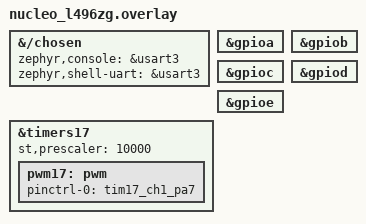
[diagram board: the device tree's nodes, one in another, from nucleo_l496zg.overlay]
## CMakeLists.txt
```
cmake_minimum_required(VERSION 3.20.0)

find_package(Zephyr REQUIRED HINTS $ENV{ZEPHYR_BASE})

project(mecanum)

target_sources(app PRIVATE
    src/main.c
    src/zephyr_motor.c
    src/zephyr_encoder.c
    src/zephyr_accelmotor.c
    src/zephyr_ps2.c
)

target_include_directories(app PRIVATE src)
```

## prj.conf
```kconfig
CONFIG_GPIO=y

CONFIG_PWM=y

CONFIG_COUNTER=y

CONFIG_CONSOLE=y

CONFIG_SERIAL=y

CONFIG_LOG=y

CONFIG_LOG_MODE_IMMEDIATE=y


CONFIG_UART_INTERRUPT_DRIVEN=y

CONFIG_MAIN_STACK_SIZE=4096

CONFIG_THREAD_MONITOR=y


CONFIG_CLOCK_CONTROL=y

CONFIG_PINCTRL=y

CONFIG_FPU=y

CONFIG_FPU_SHARING=y
```

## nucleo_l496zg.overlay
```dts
/*
 * Overlay for mecanum project on NUCLEO-L496ZG.
 *
 * Notes:
 * - Motor direction, PS2, and speed sensors are configured via GPIO API in code.
 * - PWM for TIM1/TIM2 is already enabled in board DTS (labels pwm1 and pwm2).
 * - We additionally enable TIM17 PWM on PA7 for BR motor.
 */

&{/chosen} {
    zephyr,console = &usart3;
    zephyr,shell-uart = &usart3;
};

&gpioa {
    status = "okay";
};

&gpiob {
    status = "okay";
};

&gpioc {
    status = "okay";
};

&gpiod {
    status = "okay";
};

&gpioe {
    status = "okay";
};

&timers17 {
    status = "okay";
    st,prescaler = <10000>;

    pwm17: pwm {
        status = "okay";
        pinctrl-0 = <&tim17_ch1_pa7>;
        pinctrl-names = "default";
    };
};
```

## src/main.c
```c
#include <zephyr/kernel.h>
#include <zephyr/device.h>
#include <zephyr/drivers/gpio.h>
#include <zephyr/drivers/pwm.h>
#include <zephyr/drivers/sensor.h>
#include <zephyr/logging/log.h>

#include "zephyr_motor.h"
#include "zephyr_encoder.h"
#include "zephyr_accelmotor.h"
#include "zephyr_ps2.h"

LOG_MODULE_REGISTER(main, LOG_LEVEL_INF);

// конфигурация
#define MAX_SPEED           70      // макс. скорость в тиках/сек
#define MIN_DUTY            30      // минимальный ШИМ для трогания с места
#define STEP_SIZE           50      // шаг перемещения по кнопкам
#define ACCEL               7       // ускорение
#define MAX_FOLLOW_SPEED    500     // макс. скорость слежения
#define DT_MS               20      // период дискретизации
#define MOTOR_AUTOTEST_NO_PS2 1     // 1: автотест моторов без геймпада PS2
#define AUTOTEST_SPEED      35      // сниженный duty для щадящего теста силовой части
#define AUTOTEST_STEP_MS    2000

// ПИД коэф-ты
#define PID_P   2.2f
#define PID_I   0.4f
#define PID_D   0.01f

// моторы
static zephyr_motor_t motor_fl, motor_fr, motor_bl, motor_br;

#if !MOTOR_AUTOTEST_NO_PS2
// энкодеры
static zephyr_encoder_t enc_fl, enc_fr, enc_bl, enc_br;

// доп. функции моторов
static zephyr_accelmotor_t accel_fl, accel_fr, accel_bl, accel_br;
#endif

// PS2 контроллер
#if !MOTOR_AUTOTEST_NO_PS2
static ps2_t ps2;

// режим
static bool position_mode = false;  // false - speed mode, true - position mode
static int32_t pos_fl = 0, pos_fr = 0, pos_bl = 0, pos_br = 0;

static void update_target_positions(void) {
    zephyr_accelmotor_set_target_pos(&accel_fl, pos_fl);
    zephyr_accelmotor_set_target_pos(&accel_fr, pos_fr);
    zephyr_accelmotor_set_target_pos(&accel_bl, pos_bl);
    zephyr_accelmotor_set_target_pos(&accel_br, pos_br);
}

// переключение режимов
static void change_mode(bool mode) {
    position_mode = mode;

    if (mode) {
        // переключение всех моторов в режим position
        zephyr_accelmotor_set_run_mode(&accel_fl, ACCEL_POS);
        zephyr_accelmotor_set_run_mode(&accel_fr, ACCEL_POS);
        zephyr_accelmotor_set_run_mode(&accel_bl, ACCEL_POS);
        zephyr_accelmotor_set_run_mode(&accel_br, ACCEL_POS);

        // Обновляем текущие позиции
        pos_fl = zephyr_accelmotor_get_current_pos(&accel_fl);
        pos_fr = zephyr_accelmotor_get_current_pos(&accel_fr);
        pos_bl = zephyr_accelmotor_get_current_pos(&accel_bl);
        pos_br = zephyr_accelmotor_get_current_pos(&accel_br);

        update_target_positions();

        LOG_INF("Switched to POSITION mode");
    } else {
        // переключение всех моторов в режим speed
        zephyr_accelmotor_set_run_mode(&accel_fl, PID_SPEED);
        zephyr_accelmotor_set_run_mode(&accel_fr, PID_SPEED);
        zephyr_accelmotor_set_run_mode(&accel_bl, PID_SPEED);
        zephyr_accelmotor_set_run_mode(&accel_br, PID_SPEED);

        LOG_INF("Switched to SPEED mode");
    }
}
#endif

static K_MUTEX_DEFINE(control_lock);

// управление моторами
void motor_control_thread(void *, void *, void *) {
    LOG_INF("Motor control thread started");

    while (1) {
#if MOTOR_AUTOTEST_NO_PS2
        k_sleep(K_MSEC(100));
        continue;
#else
        static uint32_t last_print = 0;
        k_mutex_lock(&control_lock, K_FOREVER);

        // чтение энкодеров
        int32_t enc_fl_val = zephyr_encoder_get_count(&enc_fl);
        int32_t enc_fr_val = zephyr_encoder_get_count(&enc_fr);
        int32_t enc_bl_val = zephyr_encoder_get_count(&enc_bl);
        int32_t enc_br_val = zephyr_encoder_get_count(&enc_br);

        // Обновление моторов
        bool moving1 = zephyr_accelmotor_tick(&accel_fl, enc_fl_val);
        bool moving2 = zephyr_accelmotor_tick(&accel_fr, enc_fr_val);
        bool moving3 = zephyr_accelmotor_tick(&accel_bl, enc_bl_val);
        bool moving4 = zephyr_accelmotor_tick(&accel_br, enc_br_val);

        if (position_mode && !moving1 && !moving2 && !moving3 && !moving4) {
            LOG_INF("All motors stopped, switching to speed mode");
            change_mode(false);
        }

        // вывод отладочной информации
        uint32_t now = k_uptime_get_32();
        if (now - last_print > 1000) {
            last_print = now;

            if (position_mode) {
                LOG_INF("Pos: FL=%d FR=%d BL=%d BR=%d | Target: FL=%d FR=%d",
                        zephyr_accelmotor_get_current_pos(&accel_fl),
                        zephyr_accelmotor_get_current_pos(&accel_fr),
                        zephyr_accelmotor_get_current_pos(&accel_bl),
                        zephyr_accelmotor_get_current_pos(&accel_br),
                        zephyr_accelmotor_get_target_pos(&accel_fl),
                        zephyr_accelmotor_get_target_pos(&accel_fr));
            } else {
                LOG_INF("Speed: FL=%d FR=%d BL=%d BR=%d | Duty: FL=%.1f FR=%.1f",
                        zephyr_accelmotor_get_current_speed(&accel_fl),
                        zephyr_accelmotor_get_current_speed(&accel_fr),
                        zephyr_accelmotor_get_current_speed(&accel_bl),
                        zephyr_accelmotor_get_current_speed(&accel_br),
                        zephyr_accelmotor_get_duty(&accel_fl),
                        zephyr_accelmotor_get_duty(&accel_fr));
            }
        }

        k_mutex_unlock(&control_lock);
        k_sleep(K_MSEC(DT_MS));
#endif
    }
}

// PS2
void ps2_thread(void *, void *, void *) {
    LOG_INF("PS2 thread started");

    while (1) {
#if MOTOR_AUTOTEST_NO_PS2
        static int last_phase = -1;
        uint32_t phase = (k_uptime_get_32() / AUTOTEST_STEP_MS) % 3U;

        k_mutex_lock(&control_lock, K_FOREVER);

        if (phase == 0U) {
            zephyr_motor_set_speed(&motor_fl, AUTOTEST_SPEED);
            zephyr_motor_set_speed(&motor_fr, AUTOTEST_SPEED);
            zephyr_motor_set_speed(&motor_bl, AUTOTEST_SPEED);
            zephyr_motor_set_speed(&motor_br, AUTOTEST_SPEED);
        } else if (phase == 1U) {
            zephyr_motor_set_speed(&motor_fl, -AUTOTEST_SPEED);
            zephyr_motor_set_speed(&motor_fr, -AUTOTEST_SPEED);
            zephyr_motor_set_speed(&motor_bl, -AUTOTEST_SPEED);
            zephyr_motor_set_speed(&motor_br, -AUTOTEST_SPEED);
        } else {
            zephyr_motor_set_speed(&motor_fl, 0);
            zephyr_motor_set_speed(&motor_fr, 0);
            zephyr_motor_set_speed(&motor_bl, 0);
            zephyr_motor_set_speed(&motor_br, 0);
        }
        k_mutex_unlock(&control_lock);

        if ((int)phase != last_phase) {
            last_phase = (int)phase;
            if (phase == 0U) {
                LOG_INF("AUTOTEST: FORWARD");
            } else if (phase == 1U) {
                LOG_INF("AUTOTEST: BACKWARD");
            } else {
                LOG_INF("AUTOTEST: STOP");
            }
        }

        k_sleep(K_MSEC(50));
        continue;
#else
        bool success = ps2_read_gamepad(&ps2, false, 0);

        if (success) {
            k_mutex_lock(&control_lock, K_FOREVER);

            // кнопки крестовины
            if (ps2_button_pressed(&ps2, PSB_PAD_LEFT)) {
                LOG_INF("Move LEFT");
                change_mode(true);

                pos_fl += STEP_SIZE;
                pos_fr -= STEP_SIZE;
                pos_bl -= STEP_SIZE;
                pos_br += STEP_SIZE;

                update_target_positions();
            }

            if (ps2_button_pressed(&ps2, PSB_PAD_RIGHT)) {
                LOG_INF("Move RIGHT");
                change_mode(true);

                pos_fl -= STEP_SIZE;
                pos_fr += STEP_SIZE;
                pos_bl += STEP_SIZE;
                pos_br -= STEP_SIZE;

                update_target_positions();
            }

            if (ps2_button_pressed(&ps2, PSB_PAD_UP)) {
                LOG_INF("Move UP");
                change_mode(true);

                pos_fl += STEP_SIZE;
                pos_fr += STEP_SIZE;
                pos_bl += STEP_SIZE;
                pos_br += STEP_SIZE;

                update_target_positions();
            }

            if (ps2_button_pressed(&ps2, PSB_PAD_DOWN)) {
                LOG_INF("Move DOWN");
                change_mode(true);

                pos_fl -= STEP_SIZE;
                pos_fr -= STEP_SIZE;
                pos_bl -= STEP_SIZE;
                pos_br -= STEP_SIZE;

                update_target_positions();
            }

            // скоростной режим (стики)
            if (!position_mode) {
                // чтение стиков и преобразование их в скорости
                int val_lx = (int)ps2_analog(&ps2, PSS_LX) - 128;
                int val_ly = (int)ps2_analog(&ps2, PSS_LY) - 128;
                int val_rx = (int)ps2_analog(&ps2, PSS_RX) - 128;
                int val_ry = (int)ps2_analog(&ps2, PSS_RY) - 128;

                val_lx = val_lx * MAX_SPEED / 128;
                val_ly = val_ly * MAX_SPEED / 128;
                val_rx = val_rx * MAX_SPEED / 128;
                val_ry = val_ry * MAX_SPEED / 128;

                int duty_fr = val_ly + val_lx;
                int duty_fl = val_ly - val_lx;
                int duty_br = val_ly - val_lx;
                int duty_bl = val_ly + val_lx;

                // вращение
                duty_fr += val_ry - val_rx;
                duty_fl += val_ry + val_rx;
                duty_br += val_ry - val_rx;
                duty_bl += val_ry + val_rx;

                // ограничение
                if (duty_fr > MAX_SPEED) duty_fr = MAX_SPEED;
                if (duty_fr < -MAX_SPEED) duty_fr = -MAX_SPEED;
                if (duty_fl > MAX_SPEED) duty_fl = MAX_SPEED;
                if (duty_fl < -MAX_SPEED) duty_fl = -MAX_SPEED;
                if (duty_br > MAX_SPEED) duty_br = MAX_SPEED;
                if (duty_br < -MAX_SPEED) duty_br = -MAX_SPEED;
                if (duty_bl > MAX_SPEED) duty_bl = MAX_SPEED;
                if (duty_bl < -MAX_SPEED) duty_bl = -MAX_SPEED;

                zephyr_accelmotor_set_target_speed(&accel_fl, duty_fl);
                zephyr_accelmotor_set_target_speed(&accel_fr, duty_fr);
                zephyr_accelmotor_set_target_speed(&accel_bl, duty_bl);
                zephyr_accelmotor_set_target_speed(&accel_br, duty_br);
            }

            k_mutex_unlock(&control_lock);
        } else {
            k_mutex_lock(&control_lock, K_FOREVER);
            // остановка моторов при потери связи с PS2
            LOG_WRN("PS2 lost, stopping motors");
            change_mode(false);
            zephyr_accelmotor_set_target_speed(&accel_fl, 0);
            zephyr_accelmotor_set_target_speed(&accel_fr, 0);
            zephyr_accelmotor_set_target_speed(&accel_bl, 0);
            zephyr_accelmotor_set_target_speed(&accel_br, 0);
            k_mutex_unlock(&control_lock);
        }

        k_sleep(K_MSEC(50));
#endif
    }
}

static bool init_hardware(void) {
    LOG_INF("Initializing hardware...");

    const struct device *pwm_dev1 = DEVICE_DT_GET(DT_NODELABEL(pwm1));
    const struct device *pwm_dev2 = DEVICE_DT_GET(DT_NODELABEL(pwm2));
    const struct device *pwm_dev17 = DEVICE_DT_GET(DT_NODELABEL(pwm17));

    const struct device *gpio_dev_b = DEVICE_DT_GET(DT_NODELABEL(gpiob));
    const struct device *gpio_dev_e = DEVICE_DT_GET(DT_NODELABEL(gpioe));
    const struct device *gpio_dev_a = DEVICE_DT_GET(DT_NODELABEL(gpioa));
    const struct device *gpio_dev_c = DEVICE_DT_GET(DT_NODELABEL(gpioc));
    const struct device *gpio_dev_d = DEVICE_DT_GET(DT_NODELABEL(gpiod));

    // проверка устройств
    if (!device_is_ready(pwm_dev1)) {
        LOG_ERR("TIM1 not ready");
        return false;
    }
    if (!device_is_ready(pwm_dev2)) {
        LOG_ERR("TIM2 not ready");
        return false;
    }
    if (!device_is_ready(pwm_dev17)) {
        LOG_ERR("TIM17 not ready");
        return false;
    }
    if (!device_is_ready(gpio_dev_b)) {
        LOG_ERR("GPIOB not ready");
        return false;
    }
    if (!device_is_ready(gpio_dev_e)) {
        LOG_ERR("GPIOE not ready");
        return false;
    }
    if (!device_is_ready(gpio_dev_a)) {
        LOG_ERR("GPIOA not ready");
        return false;
    }
    if (!device_is_ready(gpio_dev_c)) {
        LOG_ERR("GPIOC not ready");
        return false;
    }
    if (!device_is_ready(gpio_dev_d)) {
        LOG_ERR("GPIOD not ready");
        return false;
    }

    // FL мотор: DIR PB13 (A-1B), PWM TIM1_CH1/PE9 (A-1A)
    zephyr_motor_init(&motor_fl, pwm_dev1, 1, gpio_dev_b, 13, false);
    zephyr_motor_set_min_duty(&motor_fl, MIN_DUTY);
    zephyr_motor_set_max_duty(&motor_fl, MAX_SPEED);

    // FR мотор: DIR PE10 (A-1B), PWM TIM1_CH2/PE11 (A-1A)
    zephyr_motor_init(&motor_fr, pwm_dev1, 2, gpio_dev_e, 10, false);
    zephyr_motor_set_min_duty(&motor_fr, MIN_DUTY);
    zephyr_motor_set_max_duty(&motor_fr, MAX_SPEED);

    // BL мотор: DIR PB8 (B-1B), PWM TIM2_CH1/PA0 (B-1A)
    zephyr_motor_init(&motor_bl, pwm_dev2, 1, gpio_dev_b, 8, false);
    zephyr_motor_set_min_duty(&motor_bl, MIN_DUTY);
    zephyr_motor_set_max_duty(&motor_bl, MAX_SPEED);

    // BR мотор: DIR PA5 (B-1B), PWM TIM17_CH1/PA7 (B-1A)
    zephyr_motor_init(&motor_br, pwm_dev17, 1, gpio_dev_a, 5, false);
    zephyr_motor_set_min_duty(&motor_br, MIN_DUTY);
    zephyr_motor_set_max_duty(&motor_br, MAX_SPEED);
    

#if !MOTOR_AUTOTEST_NO_PS2
    if (!zephyr_encoder_init(&enc_fl, gpio_dev_b, 6)) return false;
    if (!zephyr_encoder_init(&enc_fr, gpio_dev_c, 6)) return false;
    if (!zephyr_encoder_init(&enc_bl, gpio_dev_e, 8)) return false;
    if (!zephyr_encoder_init(&enc_br, gpio_dev_d, 3)) return false;

    // инициализация доп. функций моторов
    zephyr_accelmotor_init(&accel_fl, &motor_fl, &enc_fl);
    zephyr_accelmotor_init(&accel_fr, &motor_fr, &enc_fr);
    zephyr_accelmotor_init(&accel_bl, &motor_bl, &enc_bl);
    zephyr_accelmotor_init(&accel_br, &motor_br, &enc_br);

    // настройка параметров
    zephyr_accelmotor_set_dt(&accel_fl, DT_MS);
    zephyr_accelmotor_set_dt(&accel_fr, DT_MS);
    zephyr_accelmotor_set_dt(&accel_bl, DT_MS);
    zephyr_accelmotor_set_dt(&accel_br, DT_MS);

    zephyr_accelmotor_set_run_mode(&accel_fl, PID_SPEED);
    zephyr_accelmotor_set_run_mode(&accel_fr, PID_SPEED);
    zephyr_accelmotor_set_run_mode(&accel_bl, PID_SPEED);
    zephyr_accelmotor_set_run_mode(&accel_br, PID_SPEED);

    zephyr_accelmotor_set_acceleration(&accel_fl, ACCEL);
    zephyr_accelmotor_set_acceleration(&accel_fr, ACCEL);
    zephyr_accelmotor_set_acceleration(&accel_bl, ACCEL);
    zephyr_accelmotor_set_acceleration(&accel_br, ACCEL);

    zephyr_accelmotor_set_max_speed(&accel_fl, MAX_FOLLOW_SPEED);
    zephyr_accelmotor_set_max_speed(&accel_fr, MAX_FOLLOW_SPEED);
    zephyr_accelmotor_set_max_speed(&accel_bl, MAX_FOLLOW_SPEED);
    zephyr_accelmotor_set_max_speed(&accel_br, MAX_FOLLOW_SPEED);

    zephyr_accelmotor_set_stopzone(&accel_fl, 5);
    zephyr_accelmotor_set_stopzone(&accel_fr, 5);
    zephyr_accelmotor_set_stopzone(&accel_bl, 5);
    zephyr_accelmotor_set_stopzone(&accel_br, 5);

    // ПИД коэф-ты
    accel_fl.kp = PID_P;
    accel_fr.kp = PID_P;
    accel_bl.kp = PID_P;
    accel_br.kp = PID_P;

    accel_fl.ki = PID_I;
    accel_fr.ki = PID_I;
    accel_bl.ki = PID_I;
    accel_br.ki = PID_I;

    accel_fl.kd = PID_D;
    accel_fr.kd = PID_D;
    accel_bl.kd = PID_D;
    accel_br.kd = PID_D;
#endif

    // инициализация PS2
#if MOTOR_AUTOTEST_NO_PS2
    LOG_WRN("PS2 init skipped: MOTOR_AUTOTEST_NO_PS2=1");
#else
    if (!ps2_init(&ps2, gpio_dev_c, 8, 12, 10, 11, false, false)) {
        LOG_ERR("Failed to initialize PS2 controller");
        return false;
    } else {
        LOG_INF("PS2 controller initialized successfully");
    }
#endif

    LOG_INF("Hardware initialization complete");
    return true;
}

K_THREAD_STACK_DEFINE(motor_stack, 2048);
K_THREAD_STACK_DEFINE(ps2_stack, 2048);
static struct k_thread motor_thread_data;
static struct k_thread ps2_thread_data;

void main(void) {
    LOG_INF("Starting Mecanum robot on NUCLEO-L496ZG");
    if (!init_hardware()) {
        LOG_ERR("Hardware init failed");
        return;
    }

    k_thread_create(&motor_thread_data, motor_stack, K_THREAD_STACK_SIZEOF(motor_stack),
                    motor_control_thread, NULL, NULL, NULL, 5, 0, K_NO_WAIT);
    k_thread_name_set(&motor_thread_data, "motor_ctrl");

    k_thread_create(&ps2_thread_data, ps2_stack, K_THREAD_STACK_SIZEOF(ps2_stack),
                    ps2_thread, NULL, NULL, NULL, 4, 0, K_NO_WAIT);
    k_thread_name_set(&ps2_thread_data, "ps2_ctrl");

    LOG_INF("System ready");
}
```

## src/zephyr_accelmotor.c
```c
#include "zephyr_accelmotor.h"
#include <zephyr/logging/log.h>

LOG_MODULE_REGISTER(accelmotor, LOG_LEVEL_INF);

static int32_t iabs32(int32_t x) {
    return (x < 0) ? -x : x;
}

static float fabs32(float x) {
    return (x < 0.0f) ? -x : x;
}

static int8_t sign(float x) {
    return (x > 0) ? 1 : ((x < 0) ? -1 : 0);
}

void zephyr_accelmotor_init(zephyr_accelmotor_t *accel,
                            zephyr_motor_t *motor,
                            zephyr_encoder_t *encoder) {
    accel->motor = motor;
    accel->encoder = encoder;

    accel->ratio = 1.0f;
    accel->dt_ms = 20;
    accel->dt_sec = 0.02f;
    accel->stopzone = 8;
    accel->max_speed = 0;
    accel->acceleration = 1.0f;

    accel->run_mode = IDLE_RUN;
    accel->current_pos = 0;
    accel->last_pos = 0;
    accel->target_pos = 0;
    accel->current_speed = 0;
    accel->target_speed = 0;
    accel->duty_f = 0.0f;
    accel->last_tick_time = k_uptime_get();

    for (int i = 0; i < 3; i++) {
        accel->speed_buf[i] = 0;
    }
    accel->speed_buf_idx = 0;
    accel->filtered_speed = 0.0f;

    accel->kp = 2.0f;
    accel->ki = 0.9f;
    accel->kd = 0.1f;
    accel->integral = 0.0f;
    accel->prev_input = 0;
    accel->last_speed = 0.0f;

    accel->control_pos = 0.0f;
    accel->control_speed = 0.0f;
}

void zephyr_accelmotor_set_dt(zephyr_accelmotor_t *accel, uint32_t dt_ms) {
    accel->dt_ms = dt_ms;
    accel->dt_sec = dt_ms / 1000.0f;
}

void zephyr_accelmotor_set_ratio(zephyr_accelmotor_t *accel, float ratio) {
    accel->ratio = ratio;
}

void zephyr_accelmotor_set_stopzone(zephyr_accelmotor_t *accel, uint32_t zone) {
    accel->stopzone = zone;
}

void zephyr_accelmotor_set_run_mode(zephyr_accelmotor_t *accel, accel_run_mode_t mode) {
    accel->run_mode = mode;
    accel->integral = 0.0f;

    if (mode == ACCEL_POS) {
        accel->control_pos = (float)accel->current_pos;
        accel->control_speed = 0.0f;
    }
}

accel_run_mode_t zephyr_accelmotor_get_run_mode(zephyr_accelmotor_t *accel) {
    return accel->run_mode;
}

static int16_t filter_speed(zephyr_accelmotor_t *accel, int16_t new_speed) {
    accel->speed_buf[accel->speed_buf_idx] = new_speed;
    accel->speed_buf_idx = (accel->speed_buf_idx + 1) % 3;

    int16_t a = accel->speed_buf[0];
    int16_t b = accel->speed_buf[1];
    int16_t c = accel->speed_buf[2];

    int16_t median;
    if ((a <= b) && (a <= c)) {
        median = (b <= c) ? b : c;
    } else if ((b <= a) && (b <= c)) {
        median = (a <= c) ? a : c;
    } else {
        median = (a <= b) ? a : b;
    }

    accel->filtered_speed += (median - accel->filtered_speed) * 0.7f;
    return (int16_t)accel->filtered_speed;
}

static void pid_control(zephyr_accelmotor_t *accel, int32_t target, int32_t current, bool cutoff) {
    int32_t err = target - current;

    accel->duty_f = (float)err * accel->kp;
    accel->duty_f += (float)(accel->prev_input - current) * accel->kd / accel->dt_sec;
    accel->prev_input = current;

    accel->integral += (float)err * accel->ki * accel->dt_sec;
    accel->duty_f += accel->integral;

    uint16_t min_duty = 0;

    if (cutoff) {
        if (iabs32(err) > (int32_t)accel->stopzone) {
            accel->duty_f += sign(err) * min_duty;
        } else {
            accel->integral = 0.0f;
        }
    } else {
        if (err == 0 && target == 0) {
            accel->integral = 0.0f;
        } else {
            accel->duty_f += sign(err) * min_duty;
        }
    }

    if (accel->max_speed > 0) {
        if (accel->duty_f > accel->max_speed) accel->duty_f = (float)accel->max_speed;
        if (accel->duty_f < -accel->max_speed) accel->duty_f = -(float)accel->max_speed;
    }

    zephyr_motor_set_speed(accel->motor, (int16_t)accel->duty_f);
}

bool zephyr_accelmotor_tick(zephyr_accelmotor_t *accel, int32_t pos) {
    accel->current_pos = pos;
    uint32_t now = k_uptime_get();

    if (now - accel->last_tick_time >= accel->dt_ms) {
        accel->last_tick_time += accel->dt_ms;

        int32_t delta_pos = accel->current_pos - accel->last_pos;
        accel->current_speed = (int16_t)(delta_pos * 1000 / (int32_t)accel->dt_ms);
        accel->current_speed = filter_speed(accel, accel->current_speed);
        accel->last_pos = accel->current_pos;

        int8_t motor_dir = zephyr_motor_get_state(accel->motor);
        if (motor_dir != 0) {
            zephyr_encoder_set_direction(accel->encoder, motor_dir);
        }
        
        switch (accel->run_mode) {
            case ACCEL_POS: {
                float err = (float)(accel->target_pos - accel->control_pos);

                if (fabs32(err) > 0.1f) {
                    float accel_step = accel->acceleration * accel->dt_sec;

                    if (fabs32(err) < accel->stopzone &&
                        fabs32(accel->last_speed - accel->control_speed) < 2.0f) {
                        accel->control_pos = (float)accel->target_pos;
                        accel->control_speed = 0.0f;
                        accel_step = 0.0f;
                    }

                    if (fabs32(err) < (accel->control_speed * accel->control_speed) / (2.0f * accel->acceleration)) {
                        err = -err;
                        accel_step = (accel->control_speed * accel->control_speed) / (2.0f * fabs32(err));
                        if (sign(accel->control_speed) == sign(err)) err = -err;
                    }

                    accel->control_speed += accel_step * sign(err);

                    if (accel->max_speed > 0) {
                        float max_speed_dt = (float)accel->max_speed * accel->dt_sec;
                        if (accel->control_speed > max_speed_dt) accel->control_speed = max_speed_dt;
                        if (accel->control_speed < -max_speed_dt) accel->control_speed = -max_speed_dt;
                    }

                    accel->control_pos += accel->control_speed;
                    accel->last_speed = accel->control_speed;
                }

                pid_control(accel, (int32_t)accel->control_pos, accel->current_pos, true);
                break;
            }

            case PID_POS:
                pid_control(accel, accel->target_pos, accel->current_pos, true);
                break;

            case ACCEL_SPEED: {
                int16_t err = accel->target_speed - accel->current_speed;
                float reducer = (fabs32((float)err) < accel->acceleration) ? 1.0f : fabs32((float)err) / accel->acceleration;
                accel->duty_f += (float)sign(err) * accel->acceleration * accel->dt_sec * reducer;
                if (accel->max_speed > 0) {
                    if (accel->duty_f > accel->max_speed) accel->duty_f = (float)accel->max_speed;
                    if (accel->duty_f < -accel->max_speed) accel->duty_f = -(float)accel->max_speed;
                }
                zephyr_motor_set_speed(accel->motor, (int16_t)accel->duty_f);
                break;
            }

            case PID_SPEED:
                pid_control(accel, accel->target_speed, accel->current_speed, false);
                break;

            default:
                break;
        }
    }

    if (accel->run_mode > 1) {
        return zephyr_motor_get_state(accel->motor) != 0;
    } else {
        return (zephyr_motor_get_state(accel->motor) != 0) ||
               (iabs32(accel->target_pos - accel->current_pos) > (int32_t)accel->stopzone);
    }
}

void zephyr_accelmotor_set_target_pos(zephyr_accelmotor_t *accel, int32_t pos) {
    accel->target_pos = pos;
}

void zephyr_accelmotor_set_target_pos_deg(zephyr_accelmotor_t *accel, int32_t deg) {
    accel->target_pos = (int32_t)((float)deg * accel->ratio / 360.0f);
}

int32_t zephyr_accelmotor_get_target_pos(zephyr_accelmotor_t *accel) {
    return accel->target_pos;
}

int32_t zephyr_accelmotor_get_target_pos_deg(zephyr_accelmotor_t *accel) {
    return (int32_t)((float)accel->target_pos * 360.0f / accel->ratio);
}

void zephyr_accelmotor_set_target_speed(zephyr_accelmotor_t *accel, int16_t speed) {
    accel->target_speed = speed;
}

void zephyr_accelmotor_set_target_speed_deg(zephyr_accelmotor_t *accel, int16_t speed) {
    accel->target_speed = (int16_t)((float)speed * accel->ratio / 360.0f);
}

int16_t zephyr_accelmotor_get_target_speed(zephyr_accelmotor_t *accel) {
    return accel->target_speed;
}

int16_t zephyr_accelmotor_get_target_speed_deg(zephyr_accelmotor_t *accel) {
    return (int16_t)((float)accel->target_speed * 360.0f / accel->ratio);
}

int32_t zephyr_accelmotor_get_current_pos(zephyr_accelmotor_t *accel) {
    return accel->current_pos;
}

int32_t zephyr_accelmotor_get_current_pos_deg(zephyr_accelmotor_t *accel) {
    return (int32_t)((float)accel->current_pos * 360.0f / accel->ratio);
}

int16_t zephyr_accelmotor_get_current_speed(zephyr_accelmotor_t *accel) {
    return accel->current_speed;
}

int16_t zephyr_accelmotor_get_current_speed_deg(zephyr_accelmotor_t *accel) {
    return (int16_t)((float)accel->current_speed * 360.0f / accel->ratio);
}

float zephyr_accelmotor_get_duty(zephyr_accelmotor_t *accel) {
    return accel->duty_f;
}

void zephyr_accelmotor_set_max_speed(zephyr_accelmotor_t *accel, uint16_t speed) {
    accel->max_speed = speed;
}

void zephyr_accelmotor_set_max_speed_deg(zephyr_accelmotor_t *accel, uint16_t speed) {
    accel->max_speed = (uint16_t)((float)speed * accel->ratio / 360.0f);
}

void zephyr_accelmotor_set_acceleration(zephyr_accelmotor_t *accel, float accel_val) {
    accel->acceleration = accel_val;
}

void zephyr_accelmotor_set_acceleration_deg(zephyr_accelmotor_t *accel, float accel_val) {
    accel->acceleration = accel_val * accel->ratio / 360.0f;
}

bool zephyr_accelmotor_is_blocked(zephyr_accelmotor_t *accel) {
    uint16_t min_duty = 0;
    return (fabs32(accel->duty_f) > min_duty && accel->current_speed == 0);
}
```

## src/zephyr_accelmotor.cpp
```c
#include "zephyr_accelmotor.h"
#include <zephyr/logging/log.h>
#include <math.h>
#include <string.h>

LOG_MODULE_REGISTER(accel_motor, LOG_LEVEL_INF);

#define SIGN(x) ((x) > 0 ? 1 : ((x) < 0 ? -1 : 0))
#define MIN(a,b) ((a) < (b) ? (a) : (b))
#define MAX(a,b) ((a) > (b) ? (a) : (b))
#define ABS(x) ((x) > 0 ? (x) : -(x))

bool AccelMotor::tick(long pos) {
	_currentPos = pos;
	if (millis() - _tmr2 > _dt) {
		_tmr2 += _dt;
		_curSpeed = (long)(_currentPos - _lastPos) / _dts;
		_curSpeed = filter(_curSpeed);
		_lastPos = _currentPos;
		
		switch (_runMode) {		
		case ACCEL_POS:
			{
				long err = _targetPos - controlPos;
				if (err != 0) {
					float accelDt = _accel * _dts;
					float accel = accelDt;
					if (abs(err) < _stopzone && abs(_lastSpeed - controlSpeed) < 2) {
						controlPos = _targetPos;
						controlSpeed = 0;
						accel = 0;
					}
					if (abs(err) < (float)(controlSpeed * controlSpeed) / (2.0 * accelDt)) {
						err = -err;
						accel = (float)(controlSpeed * controlSpeed) / (2.0 * abs(err));
						if (_sign(controlSpeed) == _sign(err)) err = -err;
					}
					controlSpeed += accel * _sign(err);
					controlSpeed = constrain(controlSpeed, -_maxSpeed*_dts, _maxSpeed*_dts);
					controlPos += controlSpeed;
					_lastSpeed = controlSpeed;	
					
				}
				PIDcontrol(controlPos, _currentPos, true);
			}
			break;
		case PID_POS:				
			PIDcontrol(_targetPos, _currentPos, true);
			break;
		case ACCEL_SPEED:
			{
				int err = _targetSpeed - _curSpeed;
				float reducer = min(abs(err) / _accel, 1.0);
				_dutyF += (float)_sign(err) * _accel * _dts * reducer;
				_dutyF = constrain(_dutyF, -_maxDuty, _maxDuty);
				setSpeed(_dutyF);
			}			
			break;
		case PID_SPEED:			
			PIDcontrol(_targetSpeed, _curSpeed, false);			
			break;
		}		
	}
	if (_runMode > 1) return (getState() != 0);
	else return (getState() != 0 || abs(_targetPos - _currentPos) > _stopzone);
}

void AccelMotor::PIDcontrol(long target, long current, bool cutoff) {
	
	long err = target - current;
	_dutyF = err * kp;	
	_dutyF += (float)(_prevInput - current) * kd / _dts;
	_prevInput = current;
	integral += (float)err * ki * _dts;
	_dutyF += integral;	
	if (cutoff) {
		if (abs(err) > _stopzone) _dutyF += _sign(err)*_minDuty;
		else integral = 0;		
	} else {
		if (err == 0 && target == 0) integral = 0;
		else _dutyF += _sign(err)*_minDuty;
	}
	_dutyF = constrain(_dutyF, -_maxDuty, _maxDuty);
	setSpeed(_dutyF);
}

bool AccelMotor::isBlocked() {
	return (abs(_dutyF) > _minDuty && _curSpeed == 0);
}

// settings
void AccelMotor::setRatio(float ratio) {
	_ratio = ratio;
}
void AccelMotor::setDt(int dt) {
	_dt = dt;
	_dts = dt / 1000.0;
}
void AccelMotor::setCurrent(long pos) {	
	_currentPos = pos;
}
void AccelMotor::setRunMode(runMode mode) {
	_runMode = mode;
	if (mode == ACCEL_POS) controlPos = _currentPos;
}

// current position
long AccelMotor::getCurrent() {
	return _currentPos;
}
long AccelMotor::getCurrentDeg() {
	return (long)_currentPos * 360 / _ratio;
}

// current speed
int AccelMotor::getSpeed() {
	return _curSpeed;
}
int AccelMotor::getSpeedDeg() {
	return (long)_curSpeed * 360 / _ratio;
}
float AccelMotor::getDuty() {
	return _dutyF;
}

// target position mode
void AccelMotor::setTarget(long pos) {
	_targetPos = pos;
}
void AccelMotor::setTargetDeg(long pos) {
	_targetPos = (long)pos * _ratio / 360;	
}
long AccelMotor::getTarget() {
	return _targetPos;
}
long AccelMotor::getTargetDeg() {
	return (long)_targetPos * 360 / _ratio;
}

void AccelMotor::setStopZone(int zone) {
	_stopzone = zone;
}

// target speed mode
void AccelMotor::setTargetSpeed(int speed) {
	_targetSpeed = speed;
}
void AccelMotor::setTargetSpeedDeg(int speed) {
	_targetSpeed = (long)speed * _ratio / 360;	
}
int AccelMotor::getTargetSpeed() {
	return _targetSpeed;
}
int AccelMotor::getTargetSpeedDeg() {
	return (long)_targetSpeed * 360 / _ratio;
}

// max speed / acceleration
void AccelMotor::setMaxSpeed(int speed) {
	_maxSpeed = speed;
}
void AccelMotor::setMaxSpeedDeg(int speed) {
	_maxSpeed = (long)speed * _ratio / 360;
}
void AccelMotor::setAcceleration(float accel) {
	_accel = accel;
}
void AccelMotor::setAccelerationDeg(float accel) {
	_accel = (float)accel * _ratio / 360.0;
}


int AccelMotor::filter(int newVal) {
	_buf[_count] = newVal;
	if (++_count >= 3) _count = 0;
	int middle = 0;
	if ((_buf[0] <= _buf[1]) && (_buf[0] <= _buf[2])) {
		middle = (_buf[1] <= _buf[2]) ? _buf[1] : _buf[2];
	} else {
		if ((_buf[1] <= _buf[0]) && (_buf[1] <= _buf[2])) {
			middle = (_buf[0] <= _buf[2]) ? _buf[0] : _buf[2];
		}
		else {
			middle = (_buf[0] <= _buf[1]) ? _buf[0] : _buf[1];
		}
	}
	_middle_f += (middle-_middle_f) * 0.7;
	return _middle_f;
}
```

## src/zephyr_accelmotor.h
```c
#ifndef ZEPHYR_ACCELMOTOR_H
#define ZEPHYR_ACCELMOTOR_H

#include "zephyr_motor.h"
#include "zephyr_encoder.h"

#ifdef __cplusplus
extern "C" {
#endif

typedef enum {
    ACCEL_POS,      // позиционирование с ускорением
    PID_POS,        // ПИД позиционирование
    ACCEL_SPEED,    // скорость с ускорением
    PID_SPEED,      // ПИД скорость
    IDLE_RUN
} accel_run_mode_t;

typedef struct {
    zephyr_motor_t *motor;
    zephyr_encoder_t *encoder;

    float ratio;            // передаточное число
    uint32_t dt_ms;         // период (мс)
    float dt_sec;           // период (сек)
    uint32_t stopzone;      // зона остановки
    uint16_t max_speed;     // макс. скорость
    float acceleration;     // ускорение

    accel_run_mode_t run_mode;
    int32_t current_pos;
    int32_t last_pos;
    int32_t target_pos;
    int16_t current_speed;
    int16_t target_speed;
    float duty_f;
    uint32_t last_tick_time;

    int16_t speed_buf[3];
    uint8_t speed_buf_idx;
    float filtered_speed;

    float kp, ki, kd;
    float integral;
    int32_t prev_input;
    float last_speed;

    float control_pos;
    float control_speed;
} zephyr_accelmotor_t;

// инициализация
void zephyr_accelmotor_init(zephyr_accelmotor_t *accel,
                            zephyr_motor_t *motor,
                            zephyr_encoder_t *encoder);

bool zephyr_accelmotor_tick(zephyr_accelmotor_t *accel, int32_t pos);

// настройки
void zephyr_accelmotor_set_dt(zephyr_accelmotor_t *accel, uint32_t dt_ms);
void zephyr_accelmotor_set_ratio(zephyr_accelmotor_t *accel, float ratio);
void zephyr_accelmotor_set_stopzone(zephyr_accelmotor_t *accel, uint32_t zone);
void zephyr_accelmotor_set_run_mode(zephyr_accelmotor_t *accel, accel_run_mode_t mode);
accel_run_mode_t zephyr_accelmotor_get_run_mode(zephyr_accelmotor_t *accel);

void zephyr_accelmotor_set_target_pos(zephyr_accelmotor_t *accel, int32_t pos);
void zephyr_accelmotor_set_target_pos_deg(zephyr_accelmotor_t *accel, int32_t deg);
int32_t zephyr_accelmotor_get_target_pos(zephyr_accelmotor_t *accel);
int32_t zephyr_accelmotor_get_target_pos_deg(zephyr_accelmotor_t *accel);

void zephyr_accelmotor_set_target_speed(zephyr_accelmotor_t *accel, int16_t speed);
void zephyr_accelmotor_set_target_speed_deg(zephyr_accelmotor_t *accel, int16_t speed);
int16_t zephyr_accelmotor_get_target_speed(zephyr_accelmotor_t *accel);
int16_t zephyr_accelmotor_get_target_speed_deg(zephyr_accelmotor_t *accel);

// текущее состояние
int32_t zephyr_accelmotor_get_current_pos(zephyr_accelmotor_t *accel);
int32_t zephyr_accelmotor_get_current_pos_deg(zephyr_accelmotor_t *accel);
int16_t zephyr_accelmotor_get_current_speed(zephyr_accelmotor_t *accel);
int16_t zephyr_accelmotor_get_current_speed_deg(zephyr_accelmotor_t *accel);
float zephyr_accelmotor_get_duty(zephyr_accelmotor_t *accel);

// ограничения
void zephyr_accelmotor_set_max_speed(zephyr_accelmotor_t *accel, uint16_t speed);
void zephyr_accelmotor_set_max_speed_deg(zephyr_accelmotor_t *accel, uint16_t speed);
void zephyr_accelmotor_set_acceleration(zephyr_accelmotor_t *accel, float accel_val);
void zephyr_accelmotor_set_acceleration_deg(zephyr_accelmotor_t *accel, float accel_val);

bool zephyr_accelmotor_is_blocked(zephyr_accelmotor_t *accel);

#ifdef __cplusplus
}
#endif

#endif /* ZEPHYR_ACCELMOTOR_H */
```

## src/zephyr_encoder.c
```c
#include "zephyr_encoder.h"
#include <zephyr/logging/log.h>

LOG_MODULE_REGISTER(encoder, LOG_LEVEL_INF);


static void encoder_isr(const struct device *dev, struct gpio_callback *cb, uint32_t pins)
{
    // Получаем указатель на структуру энкодера
    zephyr_encoder_t *enc = CONTAINER_OF(cb, zephyr_encoder_t, callback);
    
    // Увеличиваем или уменьшаем счетчик в зависимости от направления
    if (enc->direction > 0) {
        enc->counter++;
    } else if (enc->direction < 0) {
        enc->counter--;
    } else {
        // Если направление не определено, считаем в плюс
        enc->counter++;
    }
}

bool zephyr_encoder_init(zephyr_encoder_t *enc, 
                         const struct device *gpio_dev, 
                         gpio_pin_t pin)
{
    enc->gpio_dev = gpio_dev;
    enc->pin = pin;
    enc->counter = 0;
    enc->last_count = 0;
    enc->last_time = k_uptime_get();
    enc->direction = 1;  // по умолчанию вперед
    
    if (!device_is_ready(gpio_dev)) {
        LOG_ERR("GPIO device not ready for encoder");
        return false;
    }
    
    // Настройка пина как вход с подтяжкой
    gpio_pin_configure(gpio_dev, pin, GPIO_INPUT | GPIO_PULL_UP);
    
    // Настройка прерывания по нарастающему фронту
    gpio_pin_interrupt_configure(gpio_dev, pin, GPIO_INT_EDGE_RISING);
    
    // Инициализация callback
    gpio_init_callback(&enc->callback, encoder_isr, BIT(pin));
    gpio_add_callback(gpio_dev, &enc->callback);
    
    LOG_INF("Encoder initialized on pin %d", pin);
    return true;
}

int32_t zephyr_encoder_get_count(zephyr_encoder_t *enc)
{
    return enc->counter;
}

int32_t zephyr_encoder_get_speed(zephyr_encoder_t *enc)
{
    int64_t now = k_uptime_get();
    int32_t current = enc->counter;
    int32_t delta = current - enc->last_count;
    int64_t dt = now - enc->last_time;
    
    if (dt > 0) {
        int32_t speed = delta * 1000 / dt;
        enc->last_count = current;
        enc->last_time = now;
        return speed;
    }
    
    return 0;
}

void zephyr_encoder_reset(zephyr_encoder_t *enc)
{
    enc->counter = 0;
    enc->last_count = 0;
    enc->last_time = k_uptime_get();
}

void zephyr_encoder_set_direction(zephyr_encoder_t *enc, int8_t dir)
{
    enc->direction = dir;
}
```

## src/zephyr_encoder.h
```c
#ifndef ZEPHYR_ENCODER_H
#define ZEPHYR_ENCODER_H

#include <zephyr/kernel.h>
#include <zephyr/device.h>
#include <zephyr/drivers/gpio.h>

#ifdef __cplusplus
extern "C" {
#endif

// структура энкодера
typedef struct {
    const struct device *gpio_dev;
    gpio_pin_t pin;
    struct gpio_callback callback;
    
    volatile int32_t counter;
    volatile int32_t last_count;
    int64_t last_time;
    
    int8_t direction;
} zephyr_encoder_t;

// Инициализация энкодера
bool zephyr_encoder_init(zephyr_encoder_t *enc, 
                         const struct device *gpio_dev, 
                         gpio_pin_t pin);

// получение текущего значение счетчика
int32_t zephyr_encoder_get_count(zephyr_encoder_t *enc);

// получение скорости
int32_t zephyr_encoder_get_speed(zephyr_encoder_t *enc);

// сброс счетчика
void zephyr_encoder_reset(zephyr_encoder_t *enc);

// обновление направления
void zephyr_encoder_set_direction(zephyr_encoder_t *enc, int8_t dir);

#ifdef __cplusplus
}
#endif

#endif /* ZEPHYR_ENCODER_H */
```

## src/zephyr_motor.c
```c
#include "zephyr_motor.h"
#include <stdlib.h>
#include <zephyr/logging/log.h>

LOG_MODULE_REGISTER(motor, LOG_LEVEL_INF);
static const uint32_t motor_pwm_period_us = 1000U;

static void set_direction(zephyr_motor_t *motor, bool dir_val) {
    gpio_pin_set(motor->gpio_dev, motor->pin_dir, dir_val);
}

static void set_pwm(zephyr_motor_t *motor, uint16_t pwm_duty, pwm_flags_t flags) {
    pwm_set(motor->pwm_dev, motor->pwm_channel,
            PWM_USEC(motor_pwm_period_us),
            PWM_USEC((uint32_t)pwm_duty * motor_pwm_period_us / motor->max_duty),
            flags);
}

void zephyr_motor_init(zephyr_motor_t *motor,
                       const struct device *pwm_dev, uint32_t pwm_channel,
                       const struct device *gpio_dev, gpio_pin_t dir_pin,
                       bool reverse) {
    motor->pwm_dev = pwm_dev;
    motor->pwm_channel = pwm_channel;
    motor->gpio_dev = gpio_dev;
    motor->pin_dir = dir_pin;
    motor->reversed = reverse;
    motor->last_mode = MOTOR_STOP;
    motor->state = 0;
    motor->min_duty = 0;
    motor->max_duty = 255;
    motor->deadtime_us = 0;

    if (!device_is_ready(pwm_dev)) {
        LOG_ERR("PWM device not ready");
        return;
    }

    if (!device_is_ready(gpio_dev)) {
        LOG_ERR("GPIO device not ready");
        return;
    }

    gpio_pin_configure(gpio_dev, dir_pin, GPIO_OUTPUT);

    set_direction(motor, 0);
    set_pwm(motor, 0, 0);

    LOG_INF("Motor initialized on PWM channel %d", pwm_channel);
}

void zephyr_motor_run(zephyr_motor_t *motor, motor_mode_t mode, int16_t duty) {
    if (motor->deadtime_us > 0 && mode != motor->last_mode) {
        motor->last_mode = mode;
        set_direction(motor, 0);
        set_pwm(motor, 0, 0);
        k_busy_wait(motor->deadtime_us);
    }

    motor_mode_t actual_mode = mode;
    if (motor->reversed) {
        if (mode == MOTOR_FORWARD) actual_mode = MOTOR_BACKWARD;
        else if (mode == MOTOR_BACKWARD) actual_mode = MOTOR_FORWARD;
    }

    if (duty > motor->max_duty) duty = motor->max_duty;
    if (duty < -motor->max_duty) duty = -motor->max_duty;

    uint16_t pwm_duty = abs(duty);
    if (motor->min_duty > 0 && pwm_duty > 0) {
        pwm_duty = pwm_duty * (motor->max_duty - motor->min_duty) / motor->max_duty + motor->min_duty;
    }

    switch (actual_mode) {
        case MOTOR_FORWARD:
            /* L9110S uses one PWM input and one direction-select input. */
            set_direction(motor, 0);
            set_pwm(motor, pwm_duty, 0);
            motor->state = 1;
            break;

        case MOTOR_BACKWARD:
            set_direction(motor, 1);
            set_pwm(motor, pwm_duty, PWM_POLARITY_INVERTED);
            motor->state = -1;
            break;

        case MOTOR_BRAKE:
            set_direction(motor, 1);
            set_pwm(motor, motor->max_duty, 0);
            motor->state = 0;
            break;

        case MOTOR_STOP:
        default:
            set_direction(motor, 0);
            set_pwm(motor, 0, 0);
            motor->state = 0;
            break;
    }
}

void zephyr_motor_set_speed(zephyr_motor_t *motor, int16_t duty) {
    if (duty > 0) {
        zephyr_motor_run(motor, MOTOR_FORWARD, duty);
    } else if (duty < 0) {
        zephyr_motor_run(motor, MOTOR_BACKWARD, -duty);
    } else {
        zephyr_motor_run(motor, MOTOR_STOP, 0);
    }
}

int8_t zephyr_motor_get_state(zephyr_motor_t *motor) {
    return motor->state;
}

void zephyr_motor_set_min_duty(zephyr_motor_t *motor, uint16_t duty) {
    motor->min_duty = duty;
}

void zephyr_motor_set_max_duty(zephyr_motor_t *motor, uint16_t duty) {
    motor->max_duty = duty;
}

void zephyr_motor_set_resolution(zephyr_motor_t *motor, uint8_t bits) {
    motor->max_duty = (1 << bits) - 1;
}

void zephyr_motor_set_deadtime(zephyr_motor_t *motor, uint32_t us) {
    motor->deadtime_us = us;
}
```

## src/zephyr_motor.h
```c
#ifndef ZEPHYR_MOTOR_H
#define ZEPHYR_MOTOR_H

#include <zephyr/kernel.h>
#include <zephyr/device.h>
#include <zephyr/drivers/gpio.h>
#include <zephyr/drivers/pwm.h>

#ifdef __cplusplus
extern "C" {
#endif

// режимы работы моторов
typedef enum {
    MOTOR_STOP,
    MOTOR_FORWARD,
    MOTOR_BACKWARD,
    MOTOR_BRAKE
} motor_mode_t;

// структура моторов
typedef struct {
    const struct device *pwm_dev;
    uint32_t pwm_channel;
    const struct device *gpio_dev;
    gpio_pin_t pin_dir;

    bool reversed;
    motor_mode_t last_mode;
    int8_t state;

    uint16_t min_duty;
    uint16_t max_duty;
    uint32_t deadtime_us;
} zephyr_motor_t;

// инициализация
void zephyr_motor_init(zephyr_motor_t *motor,
                       const struct device *pwm_dev, uint32_t pwm_channel,
                       const struct device *gpio_dev, gpio_pin_t dir_pin,
                       bool reverse);

// основ. функции
void zephyr_motor_set_speed(zephyr_motor_t *motor, int16_t duty);
void zephyr_motor_run(zephyr_motor_t *motor, motor_mode_t mode, int16_t duty);
int8_t zephyr_motor_get_state(zephyr_motor_t *motor);

// настройки
void zephyr_motor_set_min_duty(zephyr_motor_t *motor, uint16_t duty);
void zephyr_motor_set_max_duty(zephyr_motor_t *motor, uint16_t duty);
void zephyr_motor_set_resolution(zephyr_motor_t *motor, uint8_t bits);
void zephyr_motor_set_deadtime(zephyr_motor_t *motor, uint32_t us);

#ifdef __cplusplus
}
#endif

#endif /* ZEPHYR_MOTOR_H */
```

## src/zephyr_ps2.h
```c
#ifndef ZEPHYR_PS2_H
#define ZEPHYR_PS2_H

#include <zephyr/kernel.h>
#include <zephyr/device.h>
#include <zephyr/drivers/gpio.h>

#ifdef __cplusplus
extern "C" {
#endif

// Константы кнопок
#define PSB_SELECT      0x0001
#define PSB_L3          0x0002
#define PSB_R3          0x0004
#define PSB_START       0x0008
#define PSB_PAD_UP      0x0010
#define PSB_PAD_RIGHT   0x0020
#define PSB_PAD_DOWN    0x0040
#define PSB_PAD_LEFT    0x0080
#define PSB_L2          0x0100
#define PSB_R2          0x0200
#define PSB_L1          0x0400
#define PSB_R1          0x0800
#define PSB_GREEN       0x1000
#define PSB_RED         0x2000
#define PSB_BLUE        0x4000
#define PSB_PINK        0x8000

// Константы стиков
#define PSS_RX 5
#define PSS_RY 6
#define PSS_LX 7
#define PSS_LY 8

// Структура PS2 контроллера
typedef struct {
    const struct device *gpio_dev;
    gpio_pin_t clk_pin;
    gpio_pin_t cmd_pin;
    gpio_pin_t att_pin;
    gpio_pin_t dat_pin;

    uint8_t data[21];
    uint16_t buttons;
    uint16_t last_buttons;
    uint64_t last_read;
    uint8_t read_delay;
    uint8_t controller_type;
    bool en_rumble;
    bool en_pressures;
} ps2_t;

// Инициализация
bool ps2_init(ps2_t *ps2,
              const struct device *gpio_dev,
              gpio_pin_t clk_pin, gpio_pin_t cmd_pin,
              gpio_pin_t att_pin, gpio_pin_t dat_pin,
              bool pressures, bool rumble);

// Чтение состояния
bool ps2_read_gamepad(ps2_t *ps2, bool motor1, uint8_t motor2);

// Проверка кнопок
bool ps2_button(ps2_t *ps2, uint16_t button);
bool ps2_button_pressed(ps2_t *ps2, uint16_t button);
bool ps2_button_released(ps2_t *ps2, uint16_t button);
bool ps2_new_button_state(ps2_t *ps2);
bool ps2_new_button_state_mask(ps2_t *ps2, uint16_t button);

// Аналоговые значения
uint8_t ps2_analog(ps2_t *ps2, uint8_t channel);

// Переконфигурация
void ps2_reconfig(ps2_t *ps2);

// Тип контроллера
uint8_t ps2_read_type(ps2_t *ps2);

#ifdef __cplusplus
}
#endif

#endif /* ZEPHYR_PS2_H */
```
